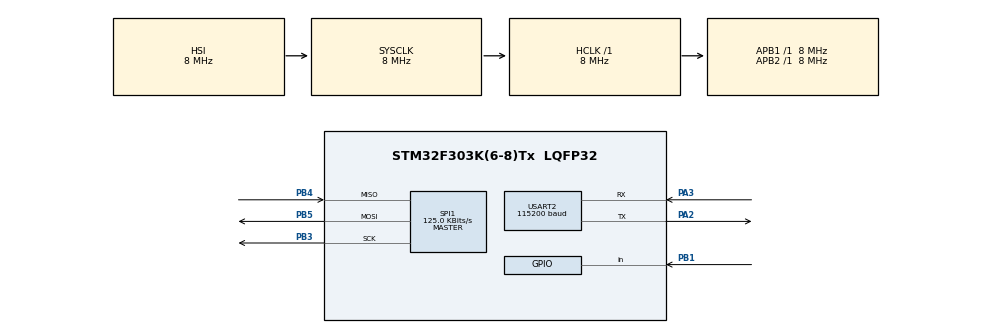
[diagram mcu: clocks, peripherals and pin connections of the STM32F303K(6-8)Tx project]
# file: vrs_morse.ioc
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Mcu.Family=STM32F3
Mcu.Name=STM32F303K(6-8)Tx
Mcu.Package=LQFP32
NVIC.PriorityGroup=NVIC_PRIORITYGROUP_4
PA13.Mode=Serial_Wire
PA13.Signal=SYS_JTMS-SWDIO
PA14.Mode=Serial_Wire
PA14.Signal=SYS_JTCK-SWCLK
PA2.Mode=Asynchronous
PA2.Signal=USART2_TX
PA3.Mode=Asynchronous
PA3.Signal=USART2_RX
PB1.GPIO_PuPd=GPIO_PULLUP
PB1.Signal=GPIO_Input
PB3.Mode=Full_Duplex_Master
PB3.Signal=SPI1_SCK
PB4.Mode=Full_Duplex_Master
PB4.Signal=SPI1_MISO
PB5.Mode=Full_Duplex_Master
PB5.Signal=SPI1_MOSI
ProjectManager.HeapSize=0x200
ProjectManager.StackSize=0x400
ProjectManager.TargetToolchain=STM32CubeIDE
RCC.AHBFreq_Value=8000000
RCC.APB1Freq_Value=8000000
RCC.APB2Freq_Value=8000000
RCC.CortexFreq_Value=8000000
RCC.HSE_VALUE=8000000
RCC.HSI_VALUE=8000000
RCC.SYSCLKFreq_VALUE=8000000
SPI1.BaudRatePrescaler=SPI_BAUDRATEPRESCALER_64
SPI1.CalculateBaudRate=125.0 KBits/s
SPI1.DataSize=SPI_DATASIZE_8BIT
SPI1.Direction=SPI_DIRECTION_2LINES
SPI1.Mode=SPI_MODE_MASTER
SPI1.VirtualType=VM_MASTER
USART2.BaudRate=115200
USART2.VirtualMode-Asynchronous=VM_ASYNC
board=custom

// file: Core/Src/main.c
/* USER CODE BEGIN Header */
/**
  ******************************************************************************
  * @file           : main.c
  * @brief          : Main program body
  ******************************************************************************
  * @attention
  *
  * Copyright (c) 2026 STMicroelectronics.
  * All rights reserved.
  *
  * This software is licensed under terms that can be found in the LICENSE file
  * in the root directory of this software component.
  * If no LICENSE file comes with this software, it is provided AS-IS.
  *
  ******************************************************************************
  */
/* USER CODE END Header */
#include "main.h"
#include "usart.h"
#include "gpio.h"
#include "spi.h"       // ADD
#include "link.h"      // ADD

/* USER CODE BEGIN Includes */
#include "app_tx.h"
/* USER CODE END Includes */

void SystemClock_Config(void);

int main(void)
{

  /* MCU Configuration--------------------------------------------------------*/

  /* Reset of all peripherals, Initializes the Flash interface and the Systick. */
  HAL_Init();

  /* Configure the system clock */
  SystemClock_Config();

  /* Initialize all configured peripherals */
  MX_GPIO_Init();
  MX_USART2_UART_Init();

  MX_SPI1_Init();      // ADD

  app_tx_init();   // tu sa zavolá log_init(&huart2)
  link_init();     // až potom init rádia (už bude log fungovať)

  /* Infinite loop */
  while (1)
  {
	  app_tx_task();
  }
}

void SystemClock_Config(void)
{
  RCC_OscInitTypeDef RCC_OscInitStruct = {0};
  RCC_ClkInitTypeDef RCC_ClkInitStruct = {0};

  /** Initializes the RCC Oscillators according to the specified parameters
  * in the RCC_OscInitTypeDef structure.
  */
  RCC_OscInitStruct.OscillatorType = RCC_OSCILLATORTYPE_HSI;
  RCC_OscInitStruct.HSIState = RCC_HSI_ON;
  RCC_OscInitStruct.HSICalibrationValue = RCC_HSICALIBRATION_DEFAULT;
  RCC_OscInitStruct.PLL.PLLState = RCC_PLL_NONE;
  if (HAL_RCC_OscConfig(&RCC_OscInitStruct) != HAL_OK)
  {
    Error_Handler();
  }

  /** Initializes the CPU, AHB and APB buses clocks
  */
  RCC_ClkInitStruct.ClockType = RCC_CLOCKTYPE_HCLK|RCC_CLOCKTYPE_SYSCLK
                              |RCC_CLOCKTYPE_PCLK1|RCC_CLOCKTYPE_PCLK2;
  RCC_ClkInitStruct.SYSCLKSource = RCC_SYSCLKSOURCE_HSI;
  RCC_ClkInitStruct.AHBCLKDivider = RCC_SYSCLK_DIV1;
  RCC_ClkInitStruct.APB1CLKDivider = RCC_HCLK_DIV1;
  RCC_ClkInitStruct.APB2CLKDivider = RCC_HCLK_DIV1;

  if (HAL_RCC_ClockConfig(&RCC_ClkInitStruct, FLASH_LATENCY_0) != HAL_OK)
  {
    Error_Handler();
  }
}

void Error_Handler(void)
{
  __disable_irq();
  while (1)
  {
  }
}
